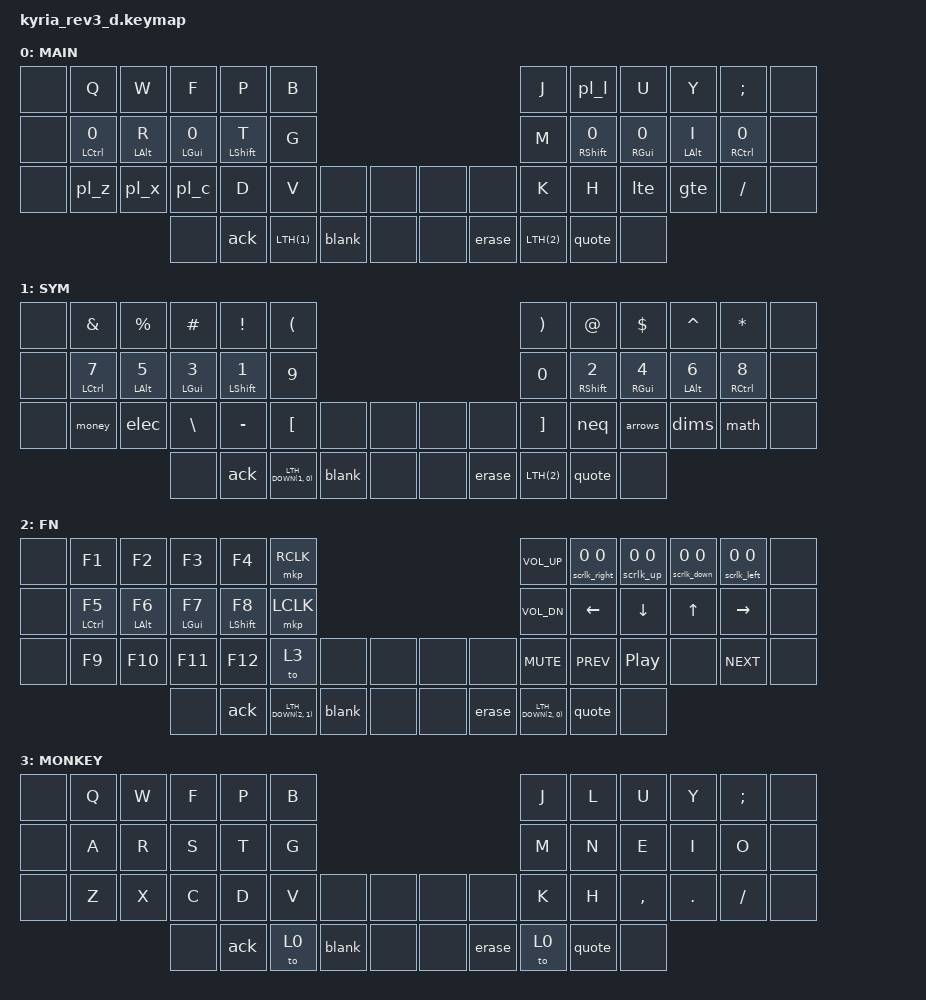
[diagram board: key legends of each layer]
/*
 * Copyright (c) 2020 The ZMK Contributors
 *
 * SPDX-License-Identifier: MIT
 */
#include <behaviors.dtsi>
#include <behaviors/unicode.dtsi>
#include <zmk-unicode/keys/polish.h>
#include <dt-bindings/zmk/keys.h>
#include <dt-bindings/zmk/pointing.h>
#include <zephyr/dt-bindings/input/input-event-codes.h>

#define LTH(layer) &lth layer layer
// Layer key pointing to a lower layer from one that was tapped on (&to): a
// higher layer always wins, so &mo of a lower one would do nothing there
#define LTH_DOWN(current, target) &lth_from_##current target target

// Scroll key taps: &msc_tick ticks every 20ms, so a 30ms press emits exactly
// one tick (speed*0.02) -- one deterministic wheel unit per tap.
#define SCRL_TICK_UP    MOVE_Y(50)
#define SCRL_TICK_DOWN  MOVE_Y(-50)
#define SCRL_TICK_LEFT  MOVE_X(-50)
#define SCRL_TICK_RIGHT MOVE_X(50)

#define KEYS_L  0  1  2  3  4  5 12 13 14 15 16 17 24 25 26 27 28 29 30 31
#define KEYS_R  6  7  8  9 10 11 18 19 20 21 22 23 32 33 34 35 36 37 38 39
#define KEYS_T 40 41 42 43 44 45 46 47 48 49

#define HM_TAPPING_TERM 280
#define HM_TAPPING_TERM_FAST 175
#define HM_PRIOR_IDLE 132

// macOS Unicode Hex Input: hold Option, type the hex code, release Option.
// Right Option is reserved for &uc, so both home-row Options are LALT: a held
// RALT would keep the hex entry open and glue consecutive letters together.
&uc {
    default-mode = <UC_MODE_MACOS>;
    macos-key = <RALT>;
    minimum-length = <4>;
};

/ {
    // One-tap-one-tick scroller for the scroll keys: stock &msc discards
    // sub-unit taps on release.
    msc_tick: msc_tick {
        compatible = "zmk,behavior-input-two-axis";
        #binding-cells = <1>;
        x-input-code = <INPUT_REL_HWHEEL>;
        y-input-code = <INPUT_REL_WHEEL>;
        trigger-period-ms = <20>;
        time-to-max-speed-ms = <0>;
        acceleration-exponent = <0>;
    };

    msc_tick_listener {
        compatible = "zmk,input-listener";
        device = <&msc_tick>;
    };

    behaviors {
        // Discrete scroll keys (QMK KC_WH_* style), since &msc drops short taps.
        // Tap (<200ms): one line at release via the &msc_tick one-tick emitter.
        // Hold: one line at 200ms, then a 1-line/100ms &msc stream until release.
        #define SCRL_KEY(ht_name, tap_name, hold_name, tick_dir, msc_dir) \
        tap_name: tap_name {                                              \
            compatible = "zmk,behavior-macro";                            \
            #binding-cells = <0>;                                         \
            wait-ms = <0>;                                                \
            tap-ms = <0>;                                                 \
            bindings                                                      \
                = <&macro_wait_time 30>                                   \
                , <&macro_press &msc_tick tick_dir>                       \
                , <&macro_release &msc_tick tick_dir>;                    \
        };                                                                \
        hold_name: hold_name {                                            \
            compatible = "zmk,behavior-macro";                            \
            #binding-cells = <0>;                                         \
            wait-ms = <0>;                                                \
            tap-ms = <0>;                                                 \
            bindings                                                      \
                = <&macro_wait_time 30>                                   \
                , <&macro_press &msc_tick tick_dir>                       \
                , <&macro_release &msc_tick tick_dir>                     \
                , <&macro_press &msc msc_dir>                             \
                , <&macro_pause_for_release>                              \
                , <&macro_release &msc msc_dir>;                          \
        };                                                                \
        ht_name: ht_name {                                                \
            compatible = "zmk,behavior-hold-tap";                         \
            #binding-cells = <2>;                                         \
            flavor = "tap-preferred";                                     \
            tapping-term-ms = <200>;                                      \
            bindings = <&hold_name>, <&tap_name>;                         \
        }

        SCRL_KEY(scrlk_up, scrlk_up_t, scrlk_up_h, SCRL_TICK_UP, SCRL_UP);
        SCRL_KEY(scrlk_down, scrlk_down_t, scrlk_down_h, SCRL_TICK_DOWN, SCRL_DOWN);
        SCRL_KEY(scrlk_left, scrlk_left_t, scrlk_left_h, SCRL_TICK_LEFT, SCRL_LEFT);
        SCRL_KEY(scrlk_right, scrlk_right_t, scrlk_right_h, SCRL_TICK_RIGHT, SCRL_RIGHT);

        // https://github.com/urob/zmk-config#timeless-homerow-mods
        hml: homerow_mods_left {
            compatible = "zmk,behavior-hold-tap";
            #binding-cells = <2>;
            bindings = <&kp>, <&kp>;

            flavor = "balanced";
            tapping-term-ms = <HM_TAPPING_TERM>;
            quick-tap-ms = <HM_TAPPING_TERM_FAST>;                // repeat on tap-into-hold
            require-prior-idle-ms = <HM_PRIOR_IDLE>;

            hold-trigger-key-positions = <KEYS_R KEYS_T>;
            hold-trigger-on-release;
        };

        hmr: homerow_mods_right {
            compatible = "zmk,behavior-hold-tap";
            #binding-cells = <2>;
            bindings = <&kp>, <&kp>;

            flavor = "balanced";
            tapping-term-ms = <HM_TAPPING_TERM>;
            quick-tap-ms = <HM_TAPPING_TERM_FAST>;
            require-prior-idle-ms = <HM_PRIOR_IDLE>;

            hold-trigger-key-positions = <KEYS_L KEYS_T>;
            hold-trigger-on-release;
        };

        // tap/hold layer
        lth: layer_tap_hold {
            compatible = "zmk,behavior-hold-tap";
            #binding-cells = <2>;
            bindings = <&mo>, <&to>;

            flavor = "hold-preferred";
            tapping-term-ms = <200>;
        };

        // tap/hold layer from a tapped-on layer (LTH_DOWN): tap goes to the
        // target, hold switches the current layer off and holds the target
        // until release, then switches the current layer back on
        #define LTH_FROM(current)                                         \
        mo_from_##current: mo_from_##current {                            \
            compatible = "zmk,behavior-macro-one-param";                  \
            #binding-cells = <1>;                                         \
            wait-ms = <0>;                                                \
            tap-ms = <0>;                                                 \
            bindings                                                      \
                = <&macro_tap &tog_off current>                           \
                , <&macro_param_1to1>                                     \
                , <&macro_press &mo MACRO_PLACEHOLDER>                    \
                , <&macro_pause_for_release>                              \
                , <&macro_param_1to1>                                     \
                , <&macro_release &mo MACRO_PLACEHOLDER>                  \
                , <&macro_tap &tog_on current>;                           \
        };                                                                \
        lth_from_##current: lth_from_##current {                          \
            compatible = "zmk,behavior-hold-tap";                         \
            #binding-cells = <2>;                                         \
            bindings = <&mo_from_##current>, <&to>;                       \
            flavor = "hold-preferred";                                    \
            tapping-term-ms = <200>;                                      \
        }

        LTH_FROM(1);  // SYM
        LTH_FROM(2);  // FN

        // &to locks the layer it switches to, and only a locking behavior can
        // switch a locked layer off. tog_on locks it again, like &to did.
        tog_off: toggle_layer_off {
            compatible = "zmk,behavior-toggle-layer";
            #binding-cells = <1>;
            toggle-mode = "off";
            locking;
        };

        tog_on: toggle_layer_on {
            compatible = "zmk,behavior-toggle-layer";
            #binding-cells = <1>;
            toggle-mode = "on";
            locking;
        };

        // morph mods
        erase: backspace_delete {
            compatible = "zmk,behavior-mod-morph";
            #binding-cells = <0>;
            bindings = <&kp BSPC>, <&kp DEL>;
            mods = <(MOD_LALT|MOD_RALT)>;
        };

        blank: space_tab {
            compatible = "zmk,behavior-mod-morph";
            #binding-cells = <0>;
            bindings = <&kp SPACE>, <&kp TAB>;
            mods = <(MOD_LALT|MOD_RALT)>;
        };

        ack: enter_esc {
            compatible = "zmk,behavior-mod-morph";
            #binding-cells = <0>;
            bindings = <&kp ENTER>, <&kp ESC>;
            mods = <(MOD_LALT|MOD_RALT)>;
        };

        quote: sqt_grave {
            compatible = "zmk,behavior-mod-morph";
            #binding-cells = <0>;
            bindings = <&kp SQT>, <&kp GRAVE>;
            mods = <(MOD_LALT|MOD_RALT)>;
        };

        // Option+key types a code point (Polish Pro style), &uc picks the
        // second one when Shift is held. Cmd/Ctrl chords skip the morph so
        // shortcuts like Cmd+Opt+S still reach the host as plain keys.
        #define UC_KEY(name, key, codes)                                  \
        name##_uc: name##_uc {                                            \
            compatible = "zmk,behavior-mod-morph";                        \
            #binding-cells = <0>;                                         \
            bindings = <&kp key>, <&uc codes>;                            \
            mods = <(MOD_LALT|MOD_RALT)>;                                 \
        };                                                                \
        name: name {                                                      \
            compatible = "zmk,behavior-mod-morph";                        \
            #binding-cells = <0>;                                         \
            bindings = <&name##_uc>, <&kp key>;                           \
            mods = <(MOD_LCTL|MOD_RCTL|MOD_LGUI|MOD_RGUI)>;               \
            keep-mods = <(MOD_LCTL|MOD_RCTL|MOD_LGUI|MOD_RGUI)>;          \
        }

        UC_KEY(pl_a, A, UC_PL_A_OGONEK);  // ą Ą
        UC_KEY(pl_c, C, UC_PL_C_ACUTE);   // ć Ć
        UC_KEY(pl_e, E, UC_PL_E_OGONEK);  // ę Ę
        UC_KEY(pl_l, L, UC_PL_L_STROKE);  // ł Ł
        UC_KEY(pl_n, N, UC_PL_N_ACUTE);   // ń Ń
        UC_KEY(pl_o, O, UC_PL_O_ACUTE);   // ó Ó
        UC_KEY(pl_s, S, UC_PL_S_ACUTE);   // ś Ś
        UC_KEY(pl_x, X, UC_PL_Z_ACUTE);   // ź Ź
        UC_KEY(pl_z, Z, UC_PL_Z_DOT);     // ż Ż
        UC_KEY(neq, EQUAL, 0x2260 0xB1); // ≠ ±
        UC_KEY(lte, COMMA, 0x2264 0);   // ≤
        UC_KEY(gte, DOT, 0x2265 0x2026); // ≥ …

        // Dedicated symbol key: tap/Shift give the first pair of code points,
        // Option/Shift+Option the second.
        #define UC_SYM(name, codes, alt_codes)                            \
        name: name {                                                      \
            compatible = "zmk,behavior-mod-morph";                        \
            #binding-cells = <0>;                                         \
            bindings = <&uc codes>, <&uc alt_codes>;                      \
            mods = <(MOD_LALT|MOD_RALT)>;                                 \
        }

        UC_SYM(money, 0xA7 0xA3, 0x20AC 0xA5);        // § £ € ¥
        UC_SYM(arrows, 0x2190 0x2192, 0x2193 0x2191); // ← → ↓ ↑
        UC_SYM(dims, 0xB0 0x2248, 0xD7 0x2300);       // ° ≈ × ⌀
        UC_SYM(math, 0x3C0 0x3BB, 0x221A 0x221E);     // π λ √ ∞
        UC_SYM(elec, 0xB5 0x3A9, 0x394 0x3C6);        // µ Ω Δ φ

        // Home-row mod tapping one of the UC_KEY morphs. The morph has to sit
        // in the tap: wrapped around the whole hold-tap, a Shift key pressed
        // while Option is already down would type ń instead of holding Shift.
        #define HM_UC(name, morph, trigger_keys)                          \
        name: name {                                                      \
            compatible = "zmk,behavior-hold-tap";                         \
            #binding-cells = <2>;                                         \
            bindings = <&kp>, <&morph>;                                   \
            flavor = "balanced";                                          \
            tapping-term-ms = <HM_TAPPING_TERM>;                          \
            quick-tap-ms = <HM_TAPPING_TERM_FAST>;                        \
            require-prior-idle-ms = <HM_PRIOR_IDLE>;                      \
            hold-trigger-key-positions = <trigger_keys>;                  \
            hold-trigger-on-release;                                      \
        }

        HM_UC(hml_a, pl_a, KEYS_R KEYS_T);
        HM_UC(hml_s, pl_s, KEYS_R KEYS_T);
        HM_UC(hmr_n, pl_n, KEYS_L KEYS_T);
        HM_UC(hmr_e, pl_e, KEYS_L KEYS_T);
        HM_UC(hmr_o, pl_o, KEYS_L KEYS_T);
    };

    keymap {
        compatible = "zmk,keymap";

        default_layer {
            display-name = "MAIN";

            bindings = <
                &none &kp Q          &kp W       &kp F         &kp P        &kp B                                 &kp J   &pl_l          &kp U         &kp Y       &kp SEMI       &none
                &none &hml_a LCTRL 0 &hml LALT R &hml_s LGUI 0 &hml LSHFT T &kp G                                 &kp M   &hmr_n RSHFT 0 &hmr_e RGUI 0 &hmr LALT I &hmr_o RCTRL 0 &none
                &none &pl_z          &pl_x       &pl_c         &kp D        &kp V  &none  &none /**/ &none &none  &kp K   &kp H          &lte          &gte        &kp FSLH       &none
                                                 &none         &ack         LTH(1) &blank &none /**/ &none &erase LTH(2)  &quote         &none
            >;
        };

        sym {
            display-name = "SYM";

            bindings = <
                &none &kp AMPS      &kp PRCNT    &kp HASH     &kp EXCL      &kp LPAR                                 &kp RPAR &kp AT        &kp DLLR     &kp CARET    &kp ASTRK     &none
                &none &hml LCTRL N7 &hml LALT N5 &hml LGUI N3 &hml LSHFT N1 &kp N9                                   &kp N0   &hmr RSHFT N2 &hmr RGUI N4 &hmr LALT N6 &hmr RCTRL N8 &none
                &none &money        &elec        &kp BSLH     &kp MINUS     &kp LBKT  &none  &none /**/ &none &none  &kp RBKT &neq          &arrows      &dims        &math         &none
                                                 &none        &ack          LTH_DOWN(1, 0) &blank &none /**/ &none &erase LTH(2) &quote     &none
            >;
        };

        fn {
            display-name = "FN";

            bindings = <
                &none &kp F1        &kp F2       &kp F3       &kp F4        &mkp RCLK                            &kp C_VOL_UP &scrlk_right 0 0 &scrlk_up 0 0 &scrlk_down 0 0 &scrlk_left 0 0 &none
                &none &hml LCTRL F5 &hml LALT F6 &hml LGUI F7 &hml LSHFT F8 &mkp LCLK                            &kp C_VOL_DN &kp LEFT         &kp DOWN      &kp UP          &kp RIGHT       &none
                &none &kp F9        &kp F10      &kp F11      &kp F12       &to 3  &none  &none /**/ &none &none &kp C_MUTE   &kp C_PREV       &kp C_PP      &none           &kp C_NEXT      &none
                                                 &none        &ack          LTH_DOWN(2, 1) &blank &none /**/ &none &erase LTH_DOWN(2, 0) &quote        &none
            >;
        };

        monkey {
            display-name = "MONKEY";

            bindings = <
                &none  &kp Q  &kp W  &kp F  &kp P  &kp B                                 &kp J  &kp L  &kp U      &kp Y    &kp SEMI  &none
                &none  &kp A  &kp R  &kp S  &kp T  &kp G                                 &kp M  &kp N  &kp E      &kp I    &kp O     &none
                &none  &kp Z  &kp X  &kp C  &kp D  &kp V  &none  &none /**/ &none &none  &kp K  &kp H  &kp COMMA  &kp DOT  &kp FSLH  &none
                                     &none  &ack   &to 0  &blank &none /**/ &none &erase &to 0  &quote &none
            >;
        };
    };
};
